# GD32E508 register map
File version: 1.0
CPU: CM33 r0p4, little endian, MPU, FPU, 4 interrupt priority bits
Registers are 32-bit, read-write, reset 0x0 unless marked. A register's access mark holds for its fields unless they carry their own. Offsets are from the block's base; [hi:lo] are bit positions; {n}, {i} and the like mark numbered series; 'fields as' and 'values as' point back to an identical list.

## CAN0 — Controller area network
Base 0x40006400
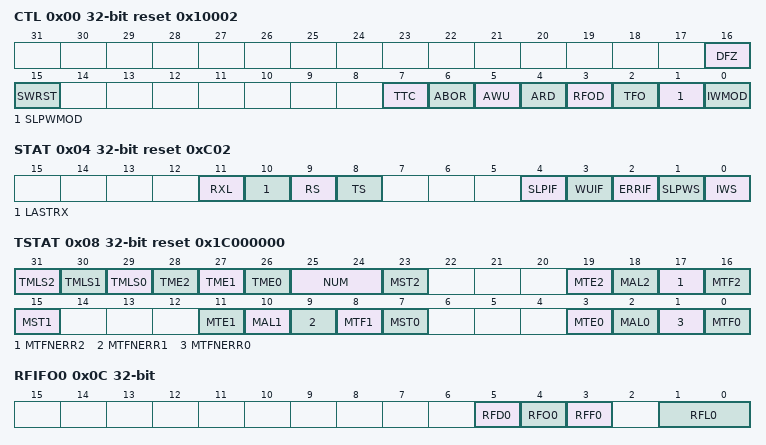
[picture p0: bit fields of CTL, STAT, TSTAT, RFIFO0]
0x00 CTL reset 0x10002 — Control register
  [16] DFZ — Debug freeze
  [15] SWRST — Software reset
  [7] TTC — Time-triggered communication
  [6] ABOR — Automatic bus-off recovery
  [5] AWU — Automatic wakeup
  [4] ARD — Automatic retransmission disable
  [3] RFOD — Receive FIFO overwrite disable
  [2] TFO — Transmit FIFO order
  [1] SLPWMOD — Sleep working mode
  [0] IWMOD — Initial working mode
0x04 STAT access per field reset 0xC02 — Status register
  [11] RXL ro — RX level
  [10] LASTRX ro — Last sample value of RX pin
  [9] RS ro — Receiving state
  [8] TS ro — Transmitting state
  [4] SLPIF rw — Status change interrupt flag of sleep working mode entering
  [3] WUIF rw — Status change interrupt flag of wakeup from sleep working mode
  [2] ERRIF rw — Error interrupt flag
  [1] SLPWS ro — Sleep working state
  [0] IWS ro — Initial working state
0x08 TSTAT access per field reset 0x1C000000 — Transmit status register
  [31] TMLS2 ro — Transmit mailbox 2 last sending in transmit FIFO
  [30] TMLS1 ro — Transmit mailbox 1 last sending in transmit FIFO
  [29] TMLS0 ro — Transmit mailbox 0 last sending in transmit FIFO
  [28] TME2 ro — Transmit mailbox 2 empty
  [27] TME1 ro — Transmit mailbox 1 empty
  [26] TME0 ro — Transmit mailbox 0 empty
  [25:24] NUM ro — number of the transmit FIFO mailbox in which the frame will be transmitted if at least one mailbox is empty
  [23] MST2 rw — Mailbox 2 stop transmitting
  [19] MTE2 rw — Mailbox 2 transmit error
  [18] MAL2 rw — Mailbox 2 arbitration lost
  [17] MTFNERR2 rw — Mailbox 2 transmit finished and no error
  [16] MTF2 rw — Mailbox 2 transmit finished
  [15] MST1 rw — Mailbox 1 stop transmitting
  [11] MTE1 rw — Mailbox 1 transmit error
  [10] MAL1 rw — Mailbox 1 arbitration lost
  [9] MTFNERR1 rw — Mailbox 1 transmit finished and no error
  [8] MTF1 rw — Mailbox 1 transmit finished
  [7] MST0 rw — Mailbox 0 stop transmitting
  [3] MTE0 rw — Mailbox 0 transmit error
  [2] MAL0 rw — Mailbox 0 arbitration lost
  [1] MTFNERR0 rw — Mailbox 0 transmit finished and no error
  [0] MTF0 rw — Mailbox 0 transmit finished
0x0C RFIFO0 access per field — Receive message FIFO0 register
  [5] RFD0 rw — Receive FIFO0 dequeue
  [4] RFO0 rw — Receive FIFO0 overfull
  [3] RFF0 rw — Receive FIFO0 full
  [1:0] RFL0 ro — Receive FIFO0 length
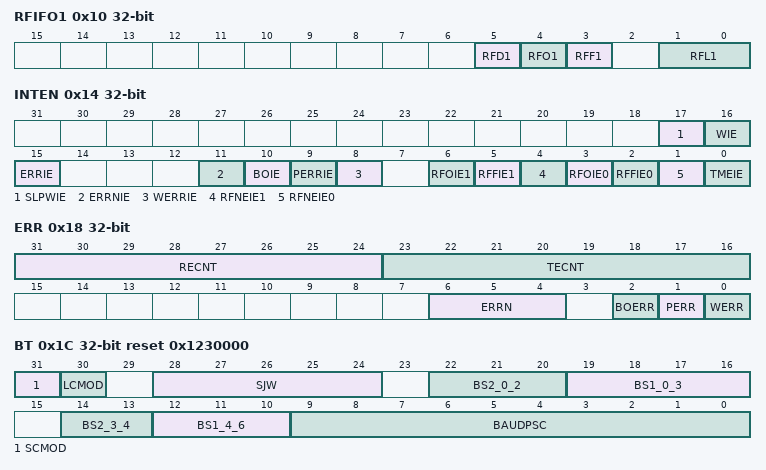
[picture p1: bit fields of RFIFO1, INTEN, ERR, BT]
0x10 RFIFO1 access per field — Receive message FIFO1 register
  [5] RFD1 rw — Receive FIFO1 dequeue
  [4] RFO1 rw — Receive FIFO1 overfull
  [3] RFF1 rw — Receive FIFO1 full
  [1:0] RFL1 ro — Receive FIFO1 length
0x14 INTEN — Interrupt enable register
  [17] SLPWIE — Sleep working interrupt enable
  [16] WIE — Wakeup interrupt enable
  [15] ERRIE — Error interrupt enable
  [11] ERRNIE — Error number interrupt enable
  [10] BOIE — Bus-off interrupt enable
  [9] PERRIE — Passive error interrupt enable
  [8] WERRIE — Warning error interrupt enable
  [6] RFOIE1 — Receive FIFO1 overfull interrupt enable
  [5] RFFIE1 — Receive FIFO1 full interrupt enable
  [4] RFNEIE1 — Receive FIFO1 not empty interrupt enable
  [3] RFOIE0 — Receive FIFO0 overfull interrupt enable
  [2] RFFIE0 — Receive FIFO0 full interrupt enable
  [1] RFNEIE0 — Receive FIFO0 not empty interrupt enable
  [0] TMEIE — Transmit mailbox empty interrupt enable
0x18 ERR access per field — Error register
  [31:24] RECNT ro — Receive Error Count defined by the CAN standard
  [23:16] TECNT ro — Transmit Error Count defined by the CAN standard
  [6:4] ERRN rw — Error number
  [2] BOERR ro — Bus-off error
  [1] PERR ro — Passive error
  [0] WERR ro — Warning error
0x1C BT reset 0x1230000 — Bit timing register
  [31] SCMOD — Silent communication mode
  [30] LCMOD — Loopback communication mode
  [28:24] SJW — Resynchronization jump width
  [22:20] BS2_0_2 — Bit segment 2
  [19:16] BS1_0_3 — Bit segment 1
  [14:13] BS2_3_4 — Bits 4:3 of BS1
  [12:10] BS1_4_6 — Bits 6:4 of BS1
  [9:0] BAUDPSC — Baud rate prescaler
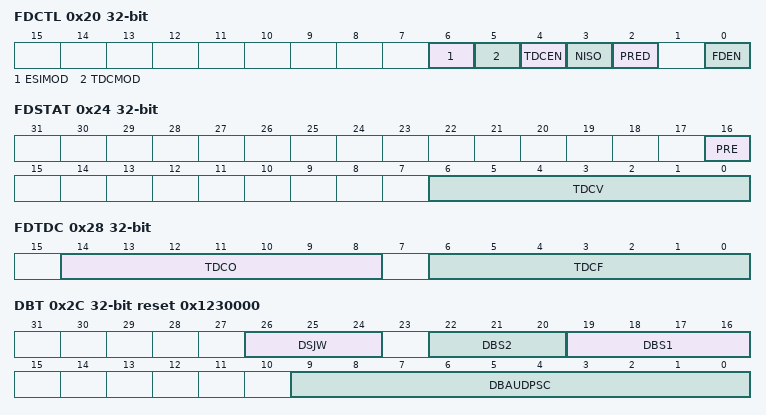
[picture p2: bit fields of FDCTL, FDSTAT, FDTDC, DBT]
0x20 FDCTL — FD control register
  [6] ESIMOD — Error state indicator mode
  [5] TDCMOD — Transmitter delay compensation mode
  [4] TDCEN — Transmitter delay compensation enable
  [3] NISO — ISO/Bosch
  [2] PRED — Protocol exception event detection disable
  [0] FDEN — FD operation enable
0x24 FDSTAT — FD status register
  [16] PRE — Protocol exception event
  [6:0] TDCV — Transmitter delay compensation value
0x28 FDTDC — FD transmitter delay compensation register
  [14:8] TDCO — Transmitter delay compensation offset
  [6:0] TDCF — Transmitter delay compensation filter
0x2C DBT reset 0x1230000 — Date Bit timing register
  [26:24] DSJW — Resynchronization jump width
  [22:20] DBS2 — Bit segment 2
  [19:16] DBS1 — Bit segment 1
  [9:0] DBAUDPSC — Baud rate prescaler
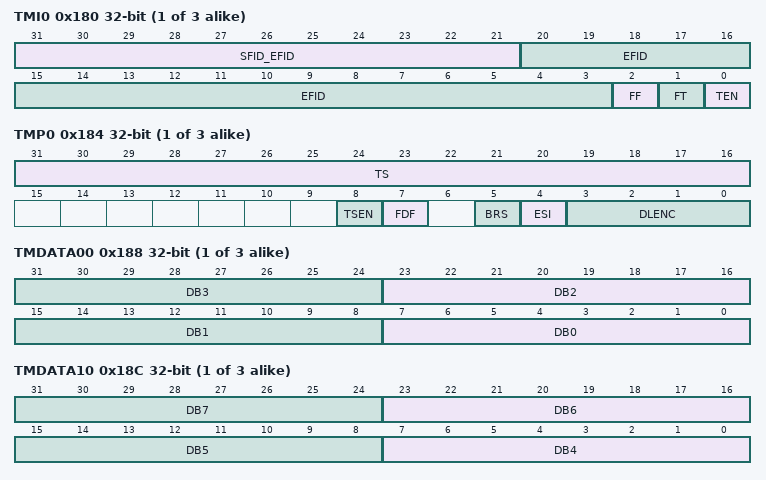
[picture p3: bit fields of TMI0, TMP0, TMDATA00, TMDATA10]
{0x180+0x10*i} TMI{i} (i=0..2) — Transmit mailbox identifier register {i}
  [31:21] SFID_EFID — The frame identifier
  [20:3] EFID — The frame identifier
  [2] FF — Frame format
  [1] FT — Frame type
  [0] TEN — Transmit enable
{0x184+0x10*i} TMP{i} (i=0..2) — Transmit mailbox property register {i}
  [31:16] TS — Time stamp
  [8] TSEN — Time stamp enable
  [7] FDF — CAN FD frame flag
  [5] BRS — Bit rate of data switch
  [4] ESI — Error status indicator
  [3:0] DLENC — Data length code
{0x188+0x10*i} TMDATA{i:02} (i=0..2) — Transmit mailbox data0 register
  [8n+7:8n] DB{n} (n=0..3) — Data byte {n}
{0xEC+0x10*i} TMDATA{i} (i=10..12) — Transmit mailbox data1 register
  [8n-25:8n-32] DB{n} (n=4..7) — Data byte {n}
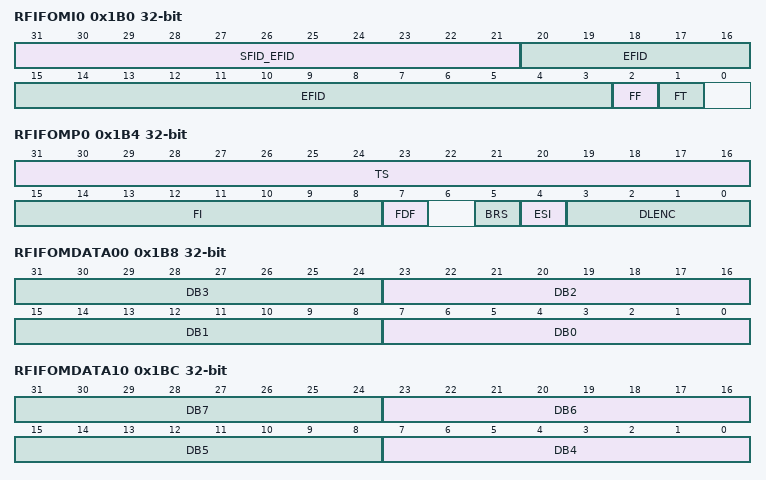
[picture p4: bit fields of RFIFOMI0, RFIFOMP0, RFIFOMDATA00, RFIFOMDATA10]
0x1B0 RFIFOMI0 ro — Receive FIFO mailbox identifier register
  [31:21] SFID_EFID — The frame identifier
  [20:3] EFID — The frame identifier
  [2] FF — Frame format
  [1] FT — Frame type
0x1B4 RFIFOMP0 ro — Receive FIFO0 mailbox property register
  [31:16] TS — Time stamp
  [15:8] FI — Filtering index
  [7] FDF — CAN FD frame flag
  [5] BRS — Bit rate of data switch
  [4] ESI — Error status indicator
  [3:0] DLENC — Data length code
0x1B8 RFIFOMDATA00 ro — Receive FIFO0 mailbox data0 register
  [8n+7:8n] DB{n} (n=0..3) — Data byte {n}
0x1BC RFIFOMDATA10 ro — Receive FIFO0 mailbox data1 register
  [8n-25:8n-32] DB{n} (n=4..7) — Data byte {n}
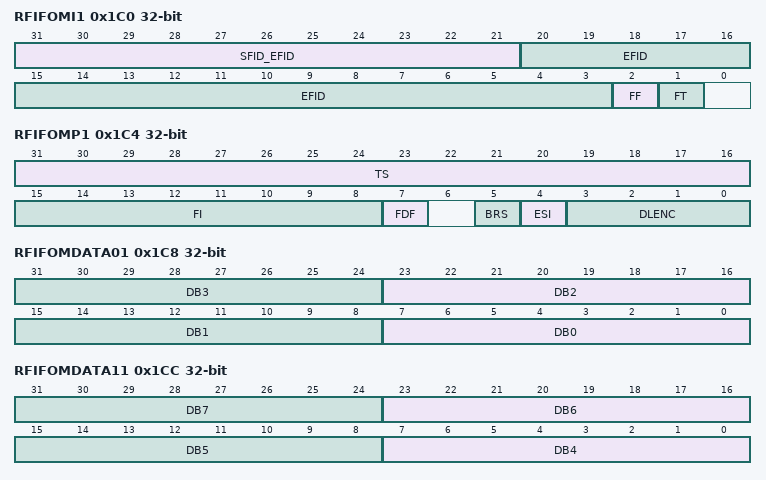
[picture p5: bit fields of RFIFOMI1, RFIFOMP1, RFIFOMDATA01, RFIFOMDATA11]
0x1C0 RFIFOMI1 ro — Receive FIFO1 mailbox identifier register
  fields as RFIFOMI0
0x1C4 RFIFOMP1 ro — Receive FIFO1 mailbox property register
  fields as RFIFOMP0
0x1C8 RFIFOMDATA01 ro — Receive FIFO1 mailbox data0 register
  [8n+7:8n] DB{n} (n=0..3) — Data byte {n}
0x1CC RFIFOMDATA11 ro — Receive FIFO1 mailbox data1 register
  [8n-25:8n-32] DB{n} (n=4..7) — Data byte {n}
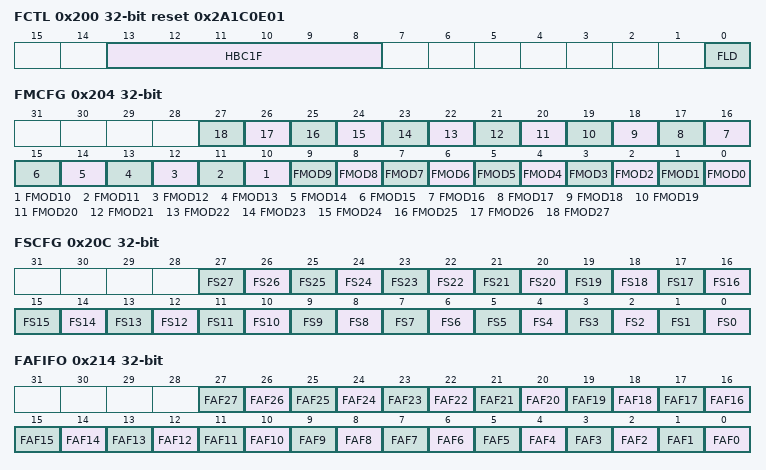
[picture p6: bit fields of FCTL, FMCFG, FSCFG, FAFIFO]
0x200 FCTL reset 0x2A1C0E01 — Filter control register
  [13:8] HBC1F — Header bank of CAN1 filter
  [0] FLD — Filter lock disable
0x204 FMCFG — Filter mode configuration register
  [n] FMOD{n} (n=0..27) — Filter mode
0x20C FSCFG — Filter scale configuration register
  [n] FS{n} (n=0..27) — Filter scale configuration
0x214 FAFIFO — Filter associated FIFO register
  [n] FAF{n} (n=0..27) — Filter {n} associated with FIFO
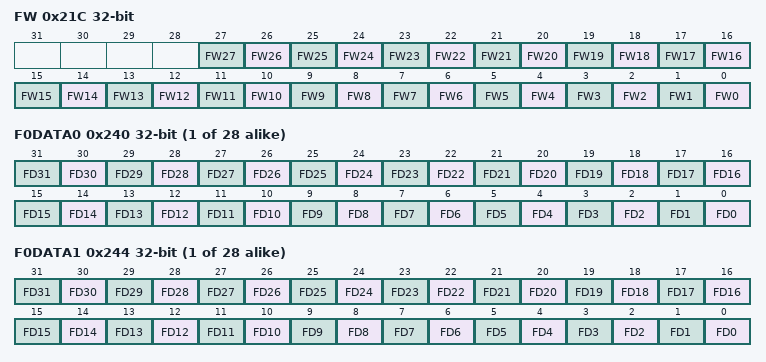
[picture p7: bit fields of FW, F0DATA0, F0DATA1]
0x21C FW — Filter working register
  [n] FW{n} (n=0..27) — Filter working
{0x240+8i} F{i}DATA0 (i=0..27) — Filter {i} data 0 register
  [n] FD{n} (n=0..31) — Filter bits
{0x244+8i} F{i}DATA1 (i=0..27) — Filter {i} data 1 register
  [n] FD{n} (n=0..31) — Filter bits

## CAN1 — Controller area network
Base 0x40006800
Registers as CAN0, without FCTL, FMCFG, FSCFG, FAFIFO, FW, F{n}DATA0 (n=0..27), F{n}DATA1 (n=0..27).

## CAN2 — Controller area network
Base 0x4000CC00
Registers as CAN0, without F{n}DATA0 (n=14..27), F{n}DATA1 (n=14..27); these are added or differ:
0x200 FCTL reset 0x2A1C0E01 — Filter control register
  [0] FLD — Filter lock disable
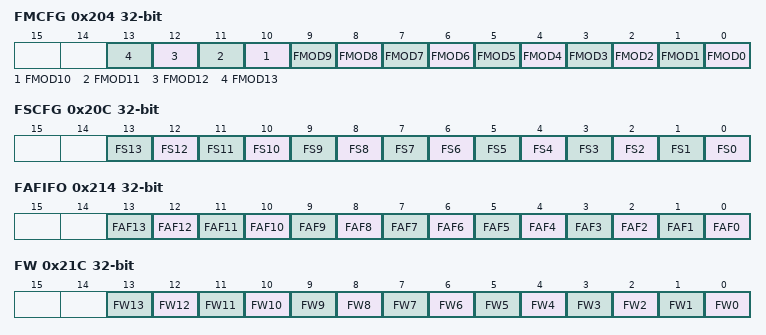
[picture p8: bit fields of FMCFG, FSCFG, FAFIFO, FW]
0x204 FMCFG — Filter mode configuration register
  [n] FMOD{n} (n=0..13) — Filter mode
0x20C FSCFG — Filter scale configuration register
  [n] FS{n} (n=0..13) — Filter scale configuration
0x214 FAFIFO — Filter associated FIFO register
  [n] FAF{n} (n=0..13) — Filter {n} associated with FIFO
0x21C FW — Filter working register
  [n] FW{n} (n=0..13) — Filter working
